VERSION ""

NS_ :

BS_:

BU_: Connectivity CCU
VAL_TABLE_ vtbSensorReqCause 15 "SNA" 2 "by Request 2" 1 "by Request 1" 0 "normal cycle" ;
VAL_TABLE_ vtbErrorDescription 255 "ERROR" ;

BO_ 2015 msg_broad_diag_request: 8 Connectivity
 SG_ sig_broad_diag_request : 0|64@1+ (1,0) [0|0] ""  CCU

BO_ 1898 msg_edc_diag_response: 8 CCU
 SG_ sig_edc_diag_response : 0|64@1+ (1,0) [0|0] ""  Connectivity

BO_ 1890 msg_edc_diag_request: 8 Connectivity
 SG_ sig_edc_diag_request : 0|64@1+ (1,0) [0|0] ""  CCU

BO_ 1897 msg_adas_diag_response: 8 CCU
 SG_ sig_adas_diag_response : 0|64@1+ (1,0) [0|0] ""  Connectivity

BO_ 1889 msg_adas_diag_request: 8 Connectivity
 SG_ sig_adas_diag_request : 0|64@1+ (1,0) [0|0] ""  CCU

BO_ 1896 msg_vdc_diag_response: 8 CCU
 SG_ sig_vdc_diag_response : 0|64@1+ (1,0) [0|0] ""  Connectivity

BO_ 1888 msg_vdc_diag_request: 8 Connectivity
 SG_ sig_vdc_diag_request : 0|64@1+ (1,0) [0|0] ""  CCU

BO_ 1887 msg_vum_diag_response: 8 CCU
 SG_ sig_vum_diag_response : 0|64@1+ (1,0) [0|0] ""  Connectivity

BO_ 1879 msg_vum_diag_request: 8 Connectivity
 SG_ sig_vum_diag_request : 0|64@1+ (1,0) [0|0] ""  CCU

BO_ 1886 msg_bdc_diag_response: 8 CCU
 SG_ sig_bdc_diag_response : 0|64@1+ (1,0) [0|0] ""  Connectivity

BO_ 1878 msg_bdc_diag_request: 8 Connectivity
 SG_ sig_bdc_diag_request : 0|64@1+ (1,0) [0|0] ""  CCU

BO_ 1885 msg_mood_diag_response: 8 CCU
 SG_ sig_mood_diag_response : 0|64@1+ (1,0) [0|0] ""  Connectivity

BO_ 1877 msg_mood_diag_request: 8 Connectivity
 SG_ sig_mood_diag_request : 0|64@1+ (1,0) [0|0] ""  CCU

BO_ 1884 msg_seat_unit_diag_response: 8 CCU
 SG_ sig_seat_unit_diag_response : 0|64@1+ (1,0) [0|0] ""  Connectivity

BO_ 1876 msg_seat_unit_diag_request: 8 Connectivity
 SG_ sig_seat_unit_diag_request : 0|64@1+ (1,0) [0|0] ""  CCU

BO_ 1883 msg_lamp_unit_diag_response: 8 CCU
 SG_ sig_lamp_unit_diag_response : 0|64@1+ (1,0) [0|0] ""  Connectivity

BO_ 1875 msg_lamp_unit_diag_request: 8 Connectivity
 SG_ sig_lamp_unit_diag_request : 0|64@1+ (1,0) [0|0] ""  CCU

BO_ 1882 msg_cluster_diag_response: 8 CCU
 SG_ sig_cluster_diag_response : 0|64@1+ (1,0) [0|0] ""  Connectivity

BO_ 1874 msg_cluster_diag_request: 8 Connectivity
 SG_ sig_cluster_diag_request : 0|64@1+ (1,0) [0|0] ""  CCU

BO_ 0 msg_mfsw_diag_response: 8 CCU
 SG_ sig_mfsw_diag_response : 0|64@1+ (1,0) [0|0] ""  Connectivity

BO_ 1873 msg_mfsw_diag_request: 8 Connectivity
 SG_ sig_mfsw_diag_request : 0|64@1+ (1,0) [0|0] ""  CCU

BO_ 1880 msg_fconsole_diag_response: 8 CCU
 SG_ sig_fconsole_diag_response : 0|64@1+ (1,0) [0|0] ""  Connectivity

BO_ 1872 msg_fconsole_diag_request: 8 Connectivity
 SG_ sig_fconsole_diag_request : 0|64@1+ (1,0) [0|0] ""  CCU

BO_ 1871 msg_bcm_diag_response: 8 CCU
 SG_ sig_bcm_diag_response : 0|64@1+ (1,0) [0|0] ""  Connectivity

BO_ 1863 msg_bcm_diag_request: 8 Connectivity
 SG_ sig_bcm_diag_request : 0|64@1+ (1,0) [0|0] ""  CCU

BO_ 1870 msg_cdc_diag_response: 8 CCU
 SG_ sig_cdc_diag_response : 0|64@1+ (1,0) [0|0] ""  Connectivity

BO_ 1862 msg_cdc_diag_request: 8 Connectivity
 SG_ sig_cdc_diag_request : 0|64@1+ (1,0) [0|0] ""  CCU

BO_ 1869 msg_rmdps_diag_response: 8 CCU
 SG_ sig_rmdps_diag_response : 0|64@1+ (1,0) [0|0] ""  Connectivity

BO_ 1861 msg_rmdps_diag_request: 8 Connectivity
 SG_ sig_rmdps_diag_request : 0|64@1+ (1,0) [0|0] ""  CCU

BO_ 1868 msg_ieb_diag_response: 8 CCU
 SG_ sig_ieb_diag_response : 0|64@1+ (1,0) [0|0] ""  Connectivity

BO_ 1860 msg_ieb_diag_request: 8 Connectivity
 SG_ sig_ieb_diag_request : 0|64@1+ (1,0) [0|0] ""  CCU

BO_ 1867 msg_pdc_diag_response: 8 CCU
 SG_ sig_pdc_diag_response : 0|64@1+ (1,0) [0|0] ""  Connectivity

BO_ 1859 msg_pdc_diag_request: 8 Connectivity
 SG_ sig_pdc_diag_request : 0|64@1+ (1,0) [0|0] ""  CCU

BO_ 1866 msg_scu_diag_response: 8 CCU
 SG_ sig_scu_diag_response : 0|64@1+ (1,0) [0|0] ""  Connectivity

BO_ 1858 msg_scu_diag_request: 8 Connectivity
 SG_ sig_scu_diag_request : 0|64@1+ (1,0) [0|0] ""  CCU

BO_ 1865 msg_tcu_diag_response: 8 CCU
 SG_ sig_tcu_diag_response : 0|64@1+ (1,0) [0|0] ""  Connectivity

BO_ 1857 msg_tcu_diag_request: 8 Connectivity
 SG_ sig_tcu_diag_request : 0|64@1+ (1,0) [0|0] ""  CCU

BO_ 1864 msg_ems_diag_response: 8 CCU
 SG_ sig_ems_diag_response : 0|64@1+ (1,0) [0|0] ""  Connectivity

BO_ 1856 msg_ems_diag_request: 8 Connectivity
 SG_ sig_ems_diag_request : 0|64@1+ (1,0) [0|0] ""  CCU

BO_ 1899 msg_conn_diag_response: 8 Connectivity
 SG_ sig_conn_diag_response : 0|64@1+ (1,0) [0|0] ""  CCU

BO_ 1891 msg_conn_diag_request: 8 CCU
 SG_ sig_conn_diag_request : 0|64@1+ (1,0) [0|0] ""  Connectivity

BO_ 1300 msg_conn_vdc: 1 Connectivity
 SG_ sig_conn_vdc : 0|8@1+ (1,0) [0|255] ""  CCU

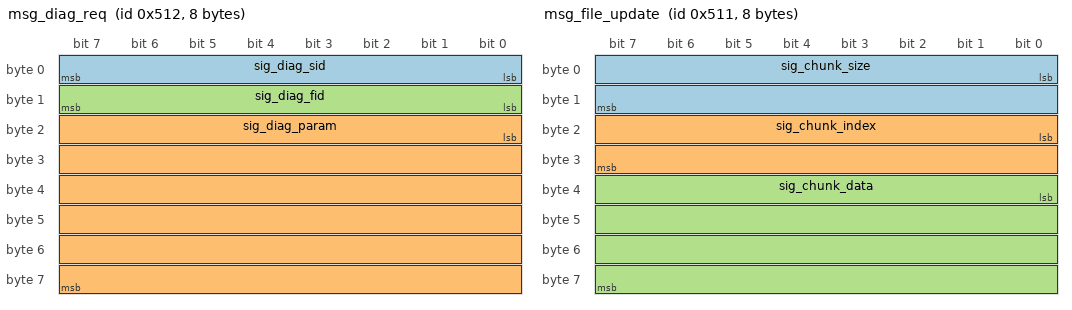
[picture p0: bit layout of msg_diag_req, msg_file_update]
BO_ 1298 msg_diag_req: 8 Connectivity
 SG_ sig_diag_sid : 0|8@1+ (1,0) [0|255] ""  CCU
 SG_ sig_diag_param : 16|48@1+ (1,0) [0|281474976710655] ""  CCU
 SG_ sig_diag_fid : 8|8@1+ (1,0) [0|255] ""  CCU

BO_ 1297 msg_file_update: 8 Connectivity
 SG_ sig_chunk_size : 0|16@1+ (1,0) [0|65535] ""  CCU
 SG_ sig_chunk_index : 16|16@1+ (1,0) [0|65535] ""  CCU
 SG_ sig_chunk_data : 32|32@1+ (1,0) [0|4294967295] ""  CCU

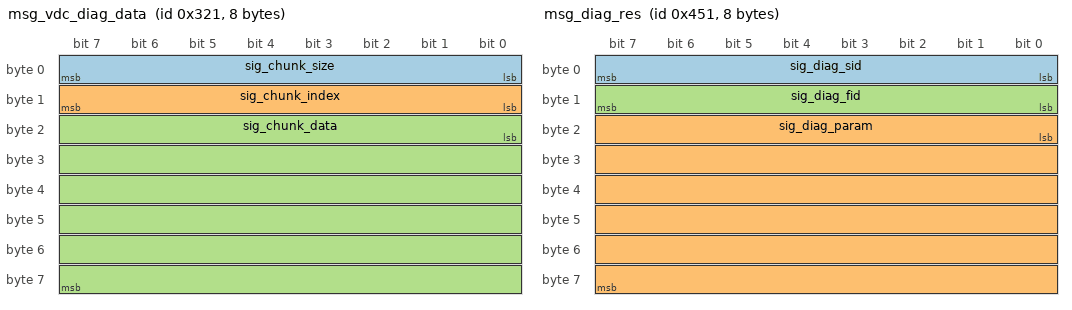
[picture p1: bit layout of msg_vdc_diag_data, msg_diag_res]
BO_ 801 msg_vdc_diag_data: 8 CCU
 SG_ sig_chunk_size : 0|8@1+ (1,0) [0|255] ""  Connectivity
 SG_ sig_chunk_index : 8|8@1+ (1,0) [0|255] ""  Connectivity
 SG_ sig_chunk_data : 16|48@1+ (1,0) [0|281474976710655] ""  Connectivity

BO_ 1105 msg_diag_res: 8 CCU
 SG_ sig_diag_sid : 0|8@1+ (1,0) [0|255] ""  Connectivity
 SG_ sig_diag_param : 16|48@1+ (1,0) [0|281474976710655] ""  Connectivity
 SG_ sig_diag_fid : 8|8@1+ (1,0) [0|255] ""  Connectivity

BA_DEF_  "DatabaseVersion" STRING ;
BA_DEF_  "Manufacturer" STRING ;
BA_DEF_ BU_  "NodeLayerModules" STRING ;
BA_DEF_  "BusType" STRING ;
BA_DEF_ SG_  "GenSigSendType" ENUM  "Cyclic","OnWrite","OnWriteWithRepetition","OnChange","OnChangeWithRepetition","IfActive","IfActiveWithRepetition","NoSigSendType","NotUsed","NotUsed","NotUsed","NotUsed","NotUsed";
BA_DEF_ BO_  "GenMsgSendType" ENUM  "Cyclic","NotUsed","NotUsed","NotUsed","NotUsed","Cyclic","NotUsed","IfActive","NoMsgSendType","NotUsed","vector_leerstring";
BA_DEF_ BO_  "GenMsgCycleTime" INT 0 50000;
BA_DEF_ BO_  "GenMsgCycleTimeFast" INT 0 50000;
BA_DEF_ BO_  "GenMsgILSupport" ENUM  "No","Yes";
BA_DEF_DEF_  "DatabaseVersion" "";
BA_DEF_DEF_  "Manufacturer" "Vector";
BA_DEF_DEF_  "NodeLayerModules" "CANoeILNLVector.dll";
BA_DEF_DEF_  "BusType" "CAN";
BA_DEF_DEF_  "GenSigSendType" "Cyclic";
BA_DEF_DEF_  "GenMsgSendType" "NoMsgSendType";
BA_DEF_DEF_  "GenMsgCycleTime" 200;
BA_DEF_DEF_  "GenMsgCycleTimeFast" 20;
BA_DEF_DEF_  "GenMsgILSupport" "Yes";
BA_ "DatabaseVersion" "1.1";
